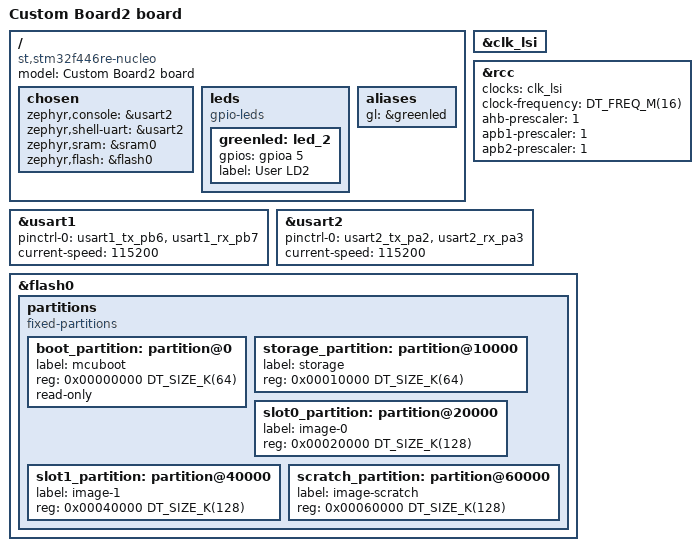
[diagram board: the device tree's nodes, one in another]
/dts-v1/;
#include <st/f4/stm32f446Xe.dtsi>
#include <zephyr/dt-bindings/input/input-event-codes.h>
#include <st/f4/stm32f446r(c-e)tx-pinctrl.dtsi>
/ {
    model= "Custom Board2 board";
    compatible="st,stm32f446re-nucleo";

    chosen{
		zephyr,console = &usart2;
		zephyr,shell-uart = &usart2;
        zephyr,sram = &sram0;
		zephyr,flash = &flash0;
    };

    leds {
        compatible = "gpio-leds";

        greenled: led_2{
        gpios = <&gpioa 5 GPIO_ACTIVE_HIGH>;
        label = "User LD2";
        };
    };

    aliases{
        gl = &greenled;
    };
};

&clk_lsi {
	status = "okay";
};

&rcc {
	clocks = <&clk_lsi>;	//Internal Clock with 16MHz
	clock-frequency = <DT_FREQ_M(16)>;
	ahb-prescaler = <1>;
	apb1-prescaler = <1>;
	apb2-prescaler = <1>;
};
&usart1 {
	pinctrl-0 = <&usart1_tx_pb6 &usart1_rx_pb7>;
	pinctrl-names = "default";
	current-speed = <115200>;
	status = "okay";
};

&usart2 {
	pinctrl-0 = <&usart2_tx_pa2 &usart2_rx_pa3>;
	pinctrl-names = "default";
	current-speed = <115200>;
	status = "okay";
};

&flash0 {
	partitions {
		compatible = "fixed-partitions";
		#address-cells = <1>;
		#size-cells = <1>;

		boot_partition: partition@0 {
			label = "mcuboot";
			reg = <0x00000000 DT_SIZE_K(64)>;
			read-only;
		};

		/*
		 * The flash starting at 0x00010000 and ending at
		 * 0x0001ffff (sectors 16-31) is reserved for use
		 * by the application.
		 */
		storage_partition: partition@10000 {
			label = "storage";
			reg = <0x00010000 DT_SIZE_K(64)>;
		};

		slot0_partition: partition@20000 {
			label = "image-0";
			reg = <0x00020000 DT_SIZE_K(128)>;
		};

		slot1_partition: partition@40000 {
			label = "image-1";
			reg = <0x00040000 DT_SIZE_K(128)>;
		};

		scratch_partition: partition@60000 {
			label = "image-scratch";
			reg = <0x00060000 DT_SIZE_K(128)>;
		};
	};
};
